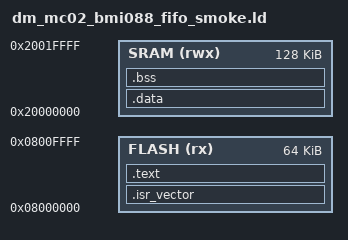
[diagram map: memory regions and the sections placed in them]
ENTRY(Reset_Handler)

MEMORY {
    FLASH (rx)  : ORIGIN = 0x08000000, LENGTH = 64K
    SRAM  (rwx) : ORIGIN = 0x20000000, LENGTH = 128K
}

SECTIONS {
    .isr_vector ORIGIN(FLASH) : { KEEP(*(.isr_vector)) } > FLASH
    .text : { *(.text*) *(.rodata*) } > FLASH
    .data : { *(.data*) } > SRAM
    .bss : { *(.bss*) *(COMMON) } > SRAM
}
